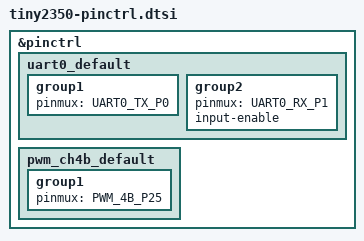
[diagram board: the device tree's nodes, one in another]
/*
 * Copyright (c) 2024 Andrew Featherstone
 * SPDX-License-Identifier: Apache-2.0
 */

#include <zephyr/dt-bindings/pinctrl/rpi-pico-rp2350a-pinctrl.h>

&pinctrl {
	uart0_default: uart0_default {
		group1 {
			pinmux = <UART0_TX_P0>;
		};

		group2 {
			pinmux = <UART0_RX_P1>;
			input-enable;
		};
	};

	pwm_ch4b_default: pwm_ch4b_default {
		group1 {
			pinmux = <PWM_4B_P25>;
		};
	};
};
